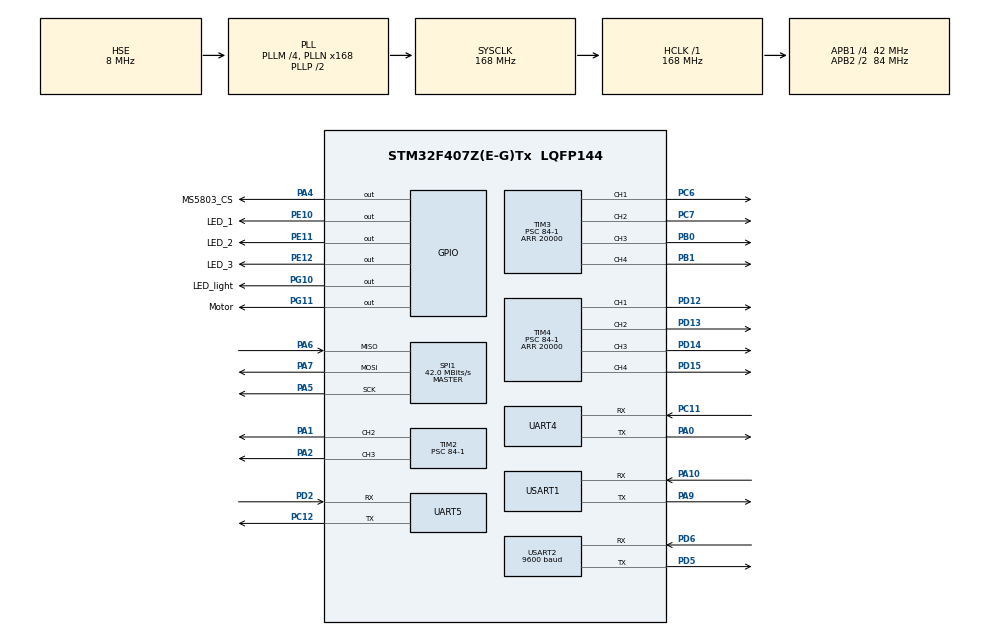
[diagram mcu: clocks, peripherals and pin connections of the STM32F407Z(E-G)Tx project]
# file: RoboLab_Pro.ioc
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Dma.Request0=UART4_RX
Dma.Request1=UART5_RX
Dma.Request2=USART2_RX
Dma.UART4_RX.0.Direction=DMA_PERIPH_TO_MEMORY
Dma.UART4_RX.0.FIFOMode=DMA_FIFOMODE_DISABLE
Dma.UART4_RX.0.Instance=DMA1_Stream2
Dma.UART4_RX.0.MemDataAlignment=DMA_MDATAALIGN_BYTE
Dma.UART4_RX.0.MemInc=DMA_MINC_ENABLE
Dma.UART4_RX.0.Mode=DMA_NORMAL
Dma.UART4_RX.0.PeriphDataAlignment=DMA_PDATAALIGN_BYTE
Dma.UART4_RX.0.PeriphInc=DMA_PINC_DISABLE
Dma.UART4_RX.0.Priority=DMA_PRIORITY_LOW
Dma.UART5_RX.1.Direction=DMA_PERIPH_TO_MEMORY
Dma.UART5_RX.1.FIFOMode=DMA_FIFOMODE_DISABLE
Dma.UART5_RX.1.Instance=DMA1_Stream0
Dma.UART5_RX.1.MemDataAlignment=DMA_MDATAALIGN_BYTE
Dma.UART5_RX.1.MemInc=DMA_MINC_ENABLE
Dma.UART5_RX.1.Mode=DMA_NORMAL
Dma.UART5_RX.1.PeriphDataAlignment=DMA_PDATAALIGN_BYTE
Dma.UART5_RX.1.PeriphInc=DMA_PINC_DISABLE
Dma.UART5_RX.1.Priority=DMA_PRIORITY_LOW
Dma.USART2_RX.2.Direction=DMA_PERIPH_TO_MEMORY
Dma.USART2_RX.2.FIFOMode=DMA_FIFOMODE_DISABLE
Dma.USART2_RX.2.Instance=DMA1_Stream5
Dma.USART2_RX.2.MemDataAlignment=DMA_MDATAALIGN_BYTE
Dma.USART2_RX.2.MemInc=DMA_MINC_ENABLE
Dma.USART2_RX.2.Mode=DMA_NORMAL
Dma.USART2_RX.2.PeriphDataAlignment=DMA_PDATAALIGN_BYTE
Dma.USART2_RX.2.PeriphInc=DMA_PINC_DISABLE
Dma.USART2_RX.2.Priority=DMA_PRIORITY_LOW
FREERTOS.INCLUDE_vTaskDelayUntil=1
FREERTOS.Tasks01=ControlTask,3,1024,ControlTask_Function,As weak,NULL,Dynamic,NULL,NULL;PressureTask,-3,128,PressureTask_Function,As weak,NULL,Dynamic,NULL,NULL;MessageTask,2,1024,MessageTask_Function,As weak,NULL,Dynamic,NULL,NULL;LedTask,-3,128,LedTask_Function,As weak,NULL,Dynamic,NULL,NULL;ImuTask,2,1024,ImuTask_Function,As weak,NULL,Dynamic,NULL,NULL;SensorTask,2,512,SensorTask_Function,As weak,NULL,Dynamic,NULL,NULL
FREERTOS.configTOTAL_HEAP_SIZE=30000
IWDG.Prescaler=IWDG_PRESCALER_32
IWDG.Reload=3000
Mcu.Family=STM32F4
Mcu.Name=STM32F407Z(E-G)Tx
Mcu.Package=LQFP144
NVIC.DMA1_Stream0_IRQn=true\:5\:0\:true\:false\:true\:false\:false\:true\:true
NVIC.DMA1_Stream2_IRQn=true\:5\:0\:true\:false\:true\:false\:false\:true\:true
NVIC.DMA1_Stream5_IRQn=true\:5\:0\:true\:false\:true\:false\:false\:true\:true
NVIC.PriorityGroup=NVIC_PRIORITYGROUP_4
NVIC.TIM7_IRQn=true\:0\:0\:false\:false\:true\:false\:false\:true\:true
NVIC.TimeBase=TIM7_IRQn
NVIC.TimeBaseIP=TIM7
NVIC.UART4_IRQn=true\:5\:0\:true\:false\:true\:false\:true\:true\:true
NVIC.UART5_IRQn=true\:5\:0\:true\:false\:true\:false\:true\:true\:true
NVIC.USART2_IRQn=true\:5\:0\:true\:false\:true\:false\:true\:true\:true
PA0-WKUP.Mode=Asynchronous
PA0-WKUP.Signal=UART4_TX
PA1.Signal=S_TIM2_CH2
PA10.Mode=Asynchronous
PA10.Signal=USART1_RX
PA13.Mode=Serial_Wire
PA13.Signal=SYS_JTMS-SWDIO
PA14.Mode=Serial_Wire
PA14.Signal=SYS_JTCK-SWCLK
PA2.Signal=S_TIM2_CH3
PA4.GPIO_Label=MS5803_CS
PA4.Signal=GPIO_Output
PA5.Mode=Full_Duplex_Master
PA5.Signal=SPI1_SCK
PA6.Mode=Full_Duplex_Master
PA6.Signal=SPI1_MISO
PA7.Mode=Full_Duplex_Master
PA7.Signal=SPI1_MOSI
PA9.Mode=Asynchronous
PA9.Signal=USART1_TX
PB0.Signal=S_TIM3_CH3
PB1.Signal=S_TIM3_CH4
PC11.Mode=Asynchronous
PC11.Signal=UART4_RX
PC12.Mode=Asynchronous
PC12.Signal=UART5_TX
PC6.Signal=S_TIM3_CH1
PC7.Signal=S_TIM3_CH2
PD12.Signal=S_TIM4_CH1
PD13.Signal=S_TIM4_CH2
PD14.Signal=S_TIM4_CH3
PD15.Signal=S_TIM4_CH4
PD2.Mode=Asynchronous
PD2.Signal=UART5_RX
PD5.Mode=Asynchronous
PD5.Signal=USART2_TX
PD6.Mode=Asynchronous
PD6.Signal=USART2_RX
PE10.GPIO_Label=LED_1
PE10.Signal=GPIO_Output
PE11.GPIO_Label=LED_2
PE11.Signal=GPIO_Output
PE12.GPIO_Label=LED_3
PE12.Signal=GPIO_Output
PG10.GPIO_Label=LED_light
PG10.Signal=GPIO_Output
PG11.GPIO_Label=Motor
PG11.Signal=GPIO_Output
PH0-OSC_IN.Mode=HSE-External-Oscillator
PH0-OSC_IN.Signal=RCC_OSC_IN
PH1-OSC_OUT.Mode=HSE-External-Oscillator
PH1-OSC_OUT.Signal=RCC_OSC_OUT
ProjectManager.HeapSize=0x200
ProjectManager.StackSize=0x400
ProjectManager.TargetToolchain=STM32CubeIDE
RCC.48MHZClocksFreq_Value=84000000
RCC.AHBFreq_Value=168000000
RCC.APB1CLKDivider=RCC_HCLK_DIV4
RCC.APB1Freq_Value=42000000
RCC.APB1TimFreq_Value=84000000
RCC.APB2CLKDivider=RCC_HCLK_DIV2
RCC.APB2Freq_Value=84000000
RCC.APB2TimFreq_Value=168000000
RCC.CortexFreq_Value=168000000
RCC.HCLKFreq_Value=168000000
RCC.HSE_VALUE=8000000
RCC.HSI_VALUE=16000000
RCC.LSE_VALUE=32768
RCC.PLLM=4
RCC.PLLN=168
RCC.PLLSourceVirtual=RCC_PLLSOURCE_HSE
RCC.SYSCLKFreq_VALUE=168000000
RCC.SYSCLKSource=RCC_SYSCLKSOURCE_PLLCLK
RCC.VCOOutputFreq_Value=336000000
SH.S_TIM2_CH2.0=TIM2_CH2,PWM Generation2 CH2
SH.S_TIM2_CH3.0=TIM2_CH3,PWM Generation3 CH3
SH.S_TIM3_CH1.0=TIM3_CH1,PWM Generation1 CH1
SH.S_TIM3_CH2.0=TIM3_CH2,PWM Generation2 CH2
SH.S_TIM3_CH3.0=TIM3_CH3,PWM Generation3 CH3
SH.S_TIM3_CH4.0=TIM3_CH4,PWM Generation4 CH4
SH.S_TIM4_CH1.0=TIM4_CH1,PWM Generation1 CH1
SH.S_TIM4_CH2.0=TIM4_CH2,PWM Generation2 CH2
SH.S_TIM4_CH3.0=TIM4_CH3,PWM Generation3 CH3
SH.S_TIM4_CH4.0=TIM4_CH4,PWM Generation4 CH4
SPI1.CalculateBaudRate=42.0 MBits/s
SPI1.Direction=SPI_DIRECTION_2LINES
SPI1.Mode=SPI_MODE_MASTER
SPI1.VirtualType=VM_MASTER
TIM1.Period=20000
TIM1.Prescaler=83
TIM2.Channel-PWM\ Generation2\ CH2=TIM_CHANNEL_2
TIM2.Channel-PWM\ Generation3\ CH3=TIM_CHANNEL_3
TIM2.Prescaler=84-1
TIM3.Channel-PWM\ Generation1\ CH1=TIM_CHANNEL_1
TIM3.Channel-PWM\ Generation2\ CH2=TIM_CHANNEL_2
TIM3.Channel-PWM\ Generation3\ CH3=TIM_CHANNEL_3
TIM3.Channel-PWM\ Generation4\ CH4=TIM_CHANNEL_4
TIM3.Period=20000
TIM3.Prescaler=84-1
TIM4.Channel-PWM\ Generation1\ CH1=TIM_CHANNEL_1
TIM4.Channel-PWM\ Generation2\ CH2=TIM_CHANNEL_2
TIM4.Channel-PWM\ Generation3\ CH3=TIM_CHANNEL_3
TIM4.Channel-PWM\ Generation4\ CH4=TIM_CHANNEL_4
TIM4.Period=20000
TIM4.Prescaler=84-1
UART4.VirtualMode=Asynchronous
UART5.VirtualMode=Asynchronous
USART1.VirtualMode=VM_ASYNC
USART2.BaudRate=9600
USART2.VirtualMode=VM_ASYNC
VP_FREERTOS_VS_CMSIS_V1.Mode=CMSIS_V1
VP_IWDG_VS_IWDG.Mode=IWDG_Activate
VP_SYS_VS_tim7.Mode=TIM7
VP_TIM1_VS_ClockSourceINT.Mode=Internal
board=custom

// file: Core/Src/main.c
/* USER CODE BEGIN Header */
/**
  ******************************************************************************
  * @file           : main.c
  * @brief          : Main program body
  ******************************************************************************
  * @attention
  *
  * <h2><center>&copy; Copyright (c) 2020 STMicroelectronics.
  * All rights reserved.</center></h2>
  *
  * This software component is licensed by ST under Ultimate Liberty license
  * SLA0044, the "License"; You may not use this file except in compliance with
  * the License. You may obtain a copy of the License at:
  *                             www.st.com/SLA0044
  *
  ******************************************************************************
  */
/* USER CODE END Header */
#include "main.h"
#include "cmsis_os.h"
#include "dma.h"
#include "iwdg.h"
#include "spi.h"
#include "tim.h"
#include "usart.h"
#include "gpio.h"

/* USER CODE BEGIN Includes */
#include "includes.h"
/* USER CODE END Includes */

void SystemClock_Config(void);
void MX_FREERTOS_Init(void);

int main(void)
{

  /* MCU Configuration--------------------------------------------------------*/

  /* Reset of all peripherals, Initializes the Flash interface and the Systick. */
  HAL_Init();

  /* Configure the system clock */
  SystemClock_Config();

  /* Initialize all configured peripherals */
  MX_GPIO_Init();
  MX_DMA_Init();
  MX_TIM1_Init();
  MX_TIM3_Init();
  MX_TIM4_Init();
  MX_USART1_UART_Init();
  MX_USART2_UART_Init();
  MX_UART4_Init();
  MX_UART5_Init();
  MX_IWDG_Init();
  MX_SPI1_Init();
  MX_TIM2_Init();
  /* USER CODE BEGIN 2 */
  pwm_init();
  MS5803aInit();
  BSP_Init();
  MX_IWDG_Init();
  /* USER CODE END 2 */

  /* Call init function for freertos objects (in freertos.c) */
  MX_FREERTOS_Init();

  /* Start scheduler */
  osKernelStart();
  /* We should never get here as control is now taken by the scheduler */
  /* Infinite loop */
  while (1)
  {

  }
}

void SystemClock_Config(void)
{
  RCC_OscInitTypeDef RCC_OscInitStruct = {0};
  RCC_ClkInitTypeDef RCC_ClkInitStruct = {0};

  /** Configure the main internal regulator output voltage
  */
  __HAL_RCC_PWR_CLK_ENABLE();
  __HAL_PWR_VOLTAGESCALING_CONFIG(PWR_REGULATOR_VOLTAGE_SCALE1);

  /** Initializes the RCC Oscillators according to the specified parameters
  * in the RCC_OscInitTypeDef structure.
  */
  RCC_OscInitStruct.OscillatorType = RCC_OSCILLATORTYPE_LSI|RCC_OSCILLATORTYPE_HSE;
  RCC_OscInitStruct.HSEState = RCC_HSE_ON;
  RCC_OscInitStruct.LSIState = RCC_LSI_ON;
  RCC_OscInitStruct.PLL.PLLState = RCC_PLL_ON;
  RCC_OscInitStruct.PLL.PLLSource = RCC_PLLSOURCE_HSE;
  RCC_OscInitStruct.PLL.PLLM = 4;
  RCC_OscInitStruct.PLL.PLLN = 168;
  RCC_OscInitStruct.PLL.PLLP = RCC_PLLP_DIV2;
  RCC_OscInitStruct.PLL.PLLQ = 4;
  if (HAL_RCC_OscConfig(&RCC_OscInitStruct) != HAL_OK)
  {
    Error_Handler();
  }

  /** Initializes the CPU, AHB and APB buses clocks
  */
  RCC_ClkInitStruct.ClockType = RCC_CLOCKTYPE_HCLK|RCC_CLOCKTYPE_SYSCLK
                              |RCC_CLOCKTYPE_PCLK1|RCC_CLOCKTYPE_PCLK2;
  RCC_ClkInitStruct.SYSCLKSource = RCC_SYSCLKSOURCE_PLLCLK;
  RCC_ClkInitStruct.AHBCLKDivider = RCC_SYSCLK_DIV1;
  RCC_ClkInitStruct.APB1CLKDivider = RCC_HCLK_DIV4;
  RCC_ClkInitStruct.APB2CLKDivider = RCC_HCLK_DIV2;

  if (HAL_RCC_ClockConfig(&RCC_ClkInitStruct, FLASH_LATENCY_5) != HAL_OK)
  {
    Error_Handler();
  }
}

void HAL_TIM_PeriodElapsedCallback(TIM_HandleTypeDef *htim)
{
  if (htim->Instance == TIM7) {
    HAL_IncTick();
  }
}

void Error_Handler(void)
{
}

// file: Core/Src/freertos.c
/* USER CODE BEGIN Header */
/**
  ******************************************************************************
  * File Name          : freertos.c
  * Description        : Code for freertos applications
  ******************************************************************************
  * @attention
  *
  * <h2><center>&copy; Copyright (c) 2020 STMicroelectronics.
  * All rights reserved.</center></h2>
  *
  * This software component is licensed by ST under Ultimate Liberty license
  * SLA0044, the "License"; You may not use this file except in compliance with
  * the License. You may obtain a copy of the License at:
  *                             www.st.com/SLA0044
  *
  ******************************************************************************
  */
/* USER CODE END Header */

#include "FreeRTOS.h"
#include "task.h"
#include "main.h"
#include "cmsis_os.h"

osThreadId ControlTaskHandle;
osThreadId PressureTaskHandle;
osThreadId MessageTaskHandle;
osThreadId LedTaskHandle;
osThreadId ImuTaskHandle;
osThreadId SensorTaskHandle;

void ControlTask_Function(void const * argument);
void PressureTask_Function(void const * argument);
void MessageTask_Function(void const * argument);
void LedTask_Function(void const * argument);
void ImuTask_Function(void const * argument);
void SensorTask_Function(void const * argument);

void MX_FREERTOS_Init(void); /* (MISRA C 2004 rule 8.1) */

/* GetIdleTaskMemory prototype (linked to static allocation support) */
void vApplicationGetIdleTaskMemory( StaticTask_t **ppxIdleTaskTCBBuffer, StackType_t **ppxIdleTaskStackBuffer, uint32_t *pulIdleTaskStackSize );

/* USER CODE BEGIN GET_IDLE_TASK_MEMORY */
static StaticTask_t xIdleTaskTCBBuffer;
static StackType_t xIdleStack[configMINIMAL_STACK_SIZE];

void vApplicationGetIdleTaskMemory( StaticTask_t **ppxIdleTaskTCBBuffer, StackType_t **ppxIdleTaskStackBuffer, uint32_t *pulIdleTaskStackSize )
{
  *ppxIdleTaskTCBBuffer = &xIdleTaskTCBBuffer;
  *ppxIdleTaskStackBuffer = &xIdleStack[0];
  *pulIdleTaskStackSize = configMINIMAL_STACK_SIZE;
  /* place for user code */
}
/* USER CODE END GET_IDLE_TASK_MEMORY */

void MX_FREERTOS_Init(void) {

  /* USER CODE BEGIN RTOS_QUEUES */
  /* add queues, ... */
	Task_Queue_Semaphore_Timers_Create();
  /* USER CODE END RTOS_QUEUES */

  /* Create the thread(s) */
  /* definition and creation of ControlTask */
  osThreadDef(ControlTask, ControlTask_Function, osPriorityRealtime, 0, 1024);
  ControlTaskHandle = osThreadCreate(osThread(ControlTask), NULL);

  /* definition and creation of PressureTask */
  osThreadDef(PressureTask, PressureTask_Function, osPriorityIdle, 0, 128);
  PressureTaskHandle = osThreadCreate(osThread(PressureTask), NULL);

  /* definition and creation of MessageTask */
  osThreadDef(MessageTask, MessageTask_Function, osPriorityHigh, 0, 1024);
  MessageTaskHandle = osThreadCreate(osThread(MessageTask), NULL);

  /* definition and creation of LedTask */
  osThreadDef(LedTask, LedTask_Function, osPriorityIdle, 0, 128);
  LedTaskHandle = osThreadCreate(osThread(LedTask), NULL);

  /* definition and creation of ImuTask */
  osThreadDef(ImuTask, ImuTask_Function, osPriorityHigh, 0, 1024);
  ImuTaskHandle = osThreadCreate(osThread(ImuTask), NULL);

  /* definition and creation of SensorTask */
  osThreadDef(SensorTask, SensorTask_Function, osPriorityHigh, 0, 512);
  SensorTaskHandle = osThreadCreate(osThread(SensorTask), NULL);

}

__weak void ControlTask_Function(void const * argument)
{
  for(;;)
  {
    osDelay(1);
  }
}

__weak void PressureTask_Function(void const * argument)
{
  for(;;)
  {
    osDelay(1);
  }
}

__weak void MessageTask_Function(void const * argument)
{
  for(;;)
  {
    osDelay(1);
  }
}

__weak void LedTask_Function(void const * argument)
{
  for(;;)
  {
    osDelay(1);
  }
}

__weak void ImuTask_Function(void const * argument)
{
  for(;;)
  {
    osDelay(1);
  }
}

__weak void SensorTask_Function(void const * argument)
{
  for(;;)
  {
    osDelay(1);
  }
}
